# cpsw_port register map
Vendor: Texas Instruments
Peripheral module from a debugger description file (folder am335x).
Registers are 32-bit, read-write, no defined reset value unless marked. A register's access mark holds for its fields unless they carry their own. Offsets are as the file gives them; lines under a group give offsets from that group; [hi:lo] are bit positions; {n}, {i} and the like mark numbered series; 'fields as' and 'values as' point back to an identical list; <NAME> marks a mode.

## cpsw_port
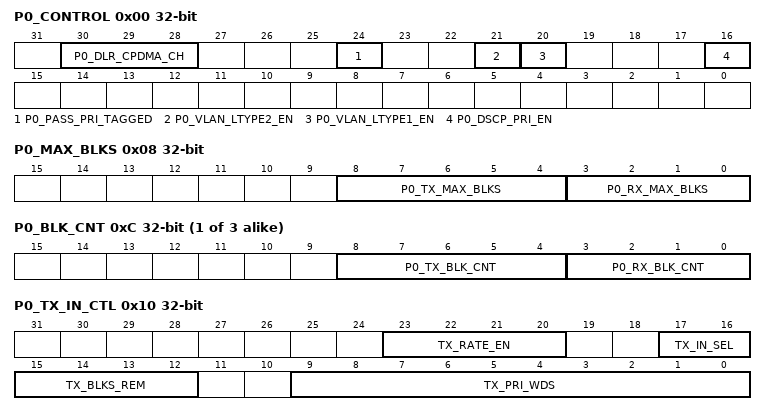
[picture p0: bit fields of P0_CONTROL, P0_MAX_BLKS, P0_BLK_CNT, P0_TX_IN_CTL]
0x00 P0_CONTROL — CPSW PORT 0 CONTROL REGISTER
  [30:28] P0_DLR_CPDMA_CH — Port 0 DLR CPDMA Channel This field indicates the CPDMA channel that DLR packets will be received on.
  [24] P0_PASS_PRI_TAGGED — Port 0 Pass Priority Tagged 0 - Priority tagged packets have the zero VID replaced with the input port P0_PORT_VLAN[11:0] 1 - Priority tagged packets are processed unchanged.
  [21] P0_VLAN_LTYPE2_EN — Port 0 VLAN LTYPE 2 enable 0 - disabled 1 - enabled
  [20] P0_VLAN_LTYPE1_EN — Port 0 VLAN LTYPE 1 enable 0 - disabled 1 - enabled
  [16] P0_DSCP_PRI_EN — Port 0 DSCP Priority Enable 0 - DSCP priority disabled 1 - DSCP priority enabled. All non-tagged IPV4 packets have their received packet priority determined by mapping the 6 TOS bits through the port DSCP priority mapping registers.
0x08 P0_MAX_BLKS — CPSW PORT 0 MAXIMUM FIFO BLOCKS REGISTER
  [8:4] P0_TX_MAX_BLKS — Transmit FIFO Maximum Blocks - This value is the maximum number of 1k memory blocks that may be allocated to the FIFO's logical transmit priority queues. 0x10 is the recommended value of p0_tx_max_blks. Port 0 should remain in flow control mode. 0xe is the minimum value tx max blks.
  [3:0] P0_RX_MAX_BLKS — Receive FIFO Maximum Blocks - This value is the maximum number of 1k memory blocks that may be allocated to the FIFO's logical receive queue. 0x4 is the recommended value. 0x3 is the minimum value rx max blks and 0x6 is the maximum value.
{0xC+0x100*i} P{i}_BLK_CNT ro (i=0..2) — CPSW PORT {i} FIFO BLOCK USAGE COUNT (READ ONLY)
  [8:4] P{i}_TX_BLK_CNT — Port {i} Transmit Block Count Usage - This value is the number of blocks allocated to the FIFO logical transmit queues.
  [3:0] P{i}_RX_BLK_CNT — Port {i} Receive Block Count Usage - This value is the number of blocks allocated to the FIFO logical receive queues.
0x10 P0_TX_IN_CTL — CPSW PORT 0 TRANSMIT FIFO CONTROL
  [23:20] TX_RATE_EN — Transmit FIFO Input Rate Enable
  [17:16] TX_IN_SEL — Transmit FIFO Input Queue Type Select 00 - Normal priority mode 01 - Dual MAC mode 10 - Rate Limit mode 11 - reserved Note that Dual MAC mode is not compatible with escalation or shaping because dual mac mode forces round robin priority on FIFO egress.
  [15:12] TX_BLKS_REM — Transmit FIFO Input Blocks to subtract in dual mac mode
  [9:0] TX_PRI_WDS — Transmit FIFO Words in queue
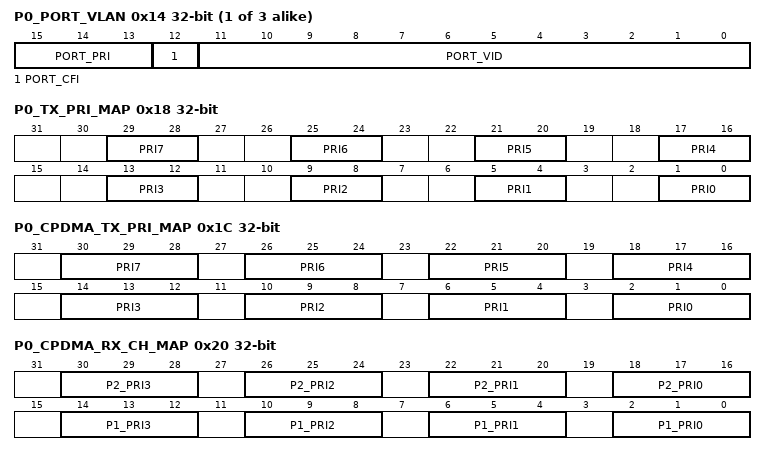
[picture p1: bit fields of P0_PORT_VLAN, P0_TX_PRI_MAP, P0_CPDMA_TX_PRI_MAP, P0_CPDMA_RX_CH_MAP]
{0x14+0x100*i} P{i}_PORT_VLAN (i=0..2) — CPSW PORT {i} VLAN REGISTER
  [15:13] PORT_PRI — Port VLAN Priority (7 is highest priority)
  [12] PORT_CFI — Port CFI bit
  [11:0] PORT_VID — Port VLAN ID
0x18 P0_TX_PRI_MAP — CPSW PORT 0 TX HEADER PRI TO SWITCH PRI MAPPING REGISTER
  [4n+1:4n] PRI{n} (n=0..7) — Priority {n} - A packet header priority of {0x0+n} is given this switch queue pri.
0x1C P0_CPDMA_TX_PRI_MAP — CPSW CPDMA TX (PORT 0 RX) PKT PRIORITY TO HEADER PRIORITY
  [4n+2:4n] PRI{n} (n=0..7) — Priority {n} - A packet pri of {0x0+n} is mapped (changed) to this header packet pri.
0x20 P0_CPDMA_RX_CH_MAP — CPSW CPDMA RX (PORT 0 TX) SWITCH PRIORITY TO DMA CHANNEL
  [4n+18:4n+16] P2_PRI{n} (n=0..3) — Port 2 Priority {n} packets go to this CPDMA Rx Channel
  [4n+2:4n] P1_PRI{n} (n=0..3) — Port 1 Priority {n} packets go to this CPDMA Rx Channel
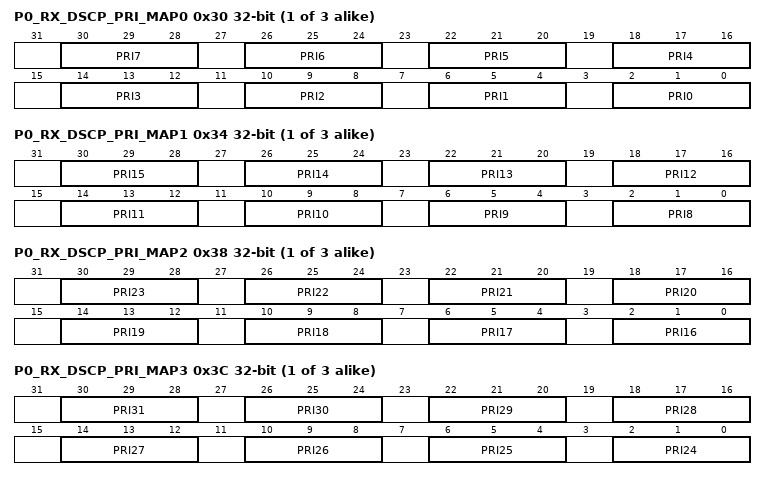
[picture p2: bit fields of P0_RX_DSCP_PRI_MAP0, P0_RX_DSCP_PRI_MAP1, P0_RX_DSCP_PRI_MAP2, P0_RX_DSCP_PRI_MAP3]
{0x30+0x100*i} P{i}_RX_DSCP_PRI_MAP0 (i=0..2) — CPSW PORT {i} RX DSCP PRIORITY TO RX PACKET MAPPING REG 0
  [4n+2:4n] PRI{n} (n=0..7) — Priority {n} - A packet TOS of 0d{n} is mapped to this received packet priority.
{0x34+0x100*i} P{i}_RX_DSCP_PRI_MAP1 (i=0..2) — CPSW PORT {i} RX DSCP PRIORITY TO RX PACKET MAPPING REG 1
  [4n-30:4n-32] PRI{n} (n=8..15) — Priority {n} - A packet TOS of 0d{n} is mapped to this received packet priority.
{0x38+0x100*i} P{i}_RX_DSCP_PRI_MAP2 (i=0..2) — CPSW PORT {i} RX DSCP PRIORITY TO RX PACKET MAPPING REG 2
  [4n-62:4n-64] PRI{n} (n=16..23) — Priority {n} - A packet TOS of 0d{n} is mapped to this received packet priority.
{0x3C+0x100*i} P{i}_RX_DSCP_PRI_MAP3 (i=0..2) — CPSW PORT {i} RX DSCP PRIORITY TO RX PACKET MAPPING REG 3
  [30:28] PRI31 — Priority 31 - A packet TOS of 0d31 is mapped to this received packet priority.
  [26:24] PRI30 — Priority 30 - A packet TOS of 0d30 is mapped to this received packet priority.
  [22:20] PRI29 — Priority 29 - A packet TOS of 0d39 is mapped to this received packet priority.
  [4n-94:4n-96] PRI{n} (n=24..28) — Priority {n} - A packet TOS of 0d{n} is mapped to this received packet priority.
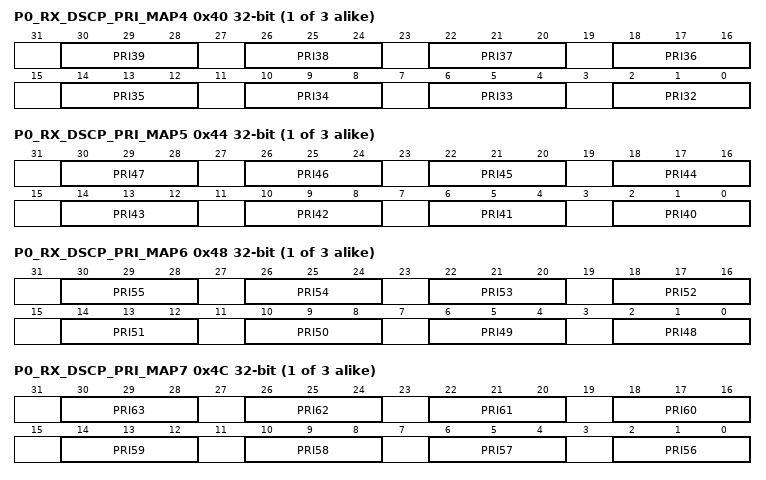
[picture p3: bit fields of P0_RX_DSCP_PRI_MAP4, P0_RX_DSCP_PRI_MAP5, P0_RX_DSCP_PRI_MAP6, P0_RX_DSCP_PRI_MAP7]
{0x40+0x100*i} P{i}_RX_DSCP_PRI_MAP4 (i=0..2) — CPSW PORT {i} RX DSCP PRIORITY TO RX PACKET MAPPING REG 4
  [4n-126:4n-128] PRI{n} (n=32..39) — Priority {n} - A packet TOS of 0d{n} is mapped to this received packet priority.
{0x44+0x100*i} P{i}_RX_DSCP_PRI_MAP5 (i=0..2) — CPSW PORT {i} RX DSCP PRIORITY TO RX PACKET MAPPING REG 5
  [4n-158:4n-160] PRI{n} (n=40..47) — Priority {n} - A packet TOS of 0d{n} is mapped to this received packet priority.
{0x48+0x100*i} P{i}_RX_DSCP_PRI_MAP6 (i=0..2) — CPSW PORT {i} RX DSCP PRIORITY TO RX PACKET MAPPING REG 6
  [4n-190:4n-192] PRI{n} (n=48..55) — Priority {n} - A packet TOS of 0d{n} is mapped to this received packet priority.
{0x4C+0x100*i} P{i}_RX_DSCP_PRI_MAP7 (i=0..2) — CPSW PORT {i} RX DSCP PRIORITY TO RX PACKET MAPPING REG 7
  [4n-222:4n-224] PRI{n} (n=56..63) — Priority {n} - A packet TOS of 0d{n} is mapped to this received packet priority.
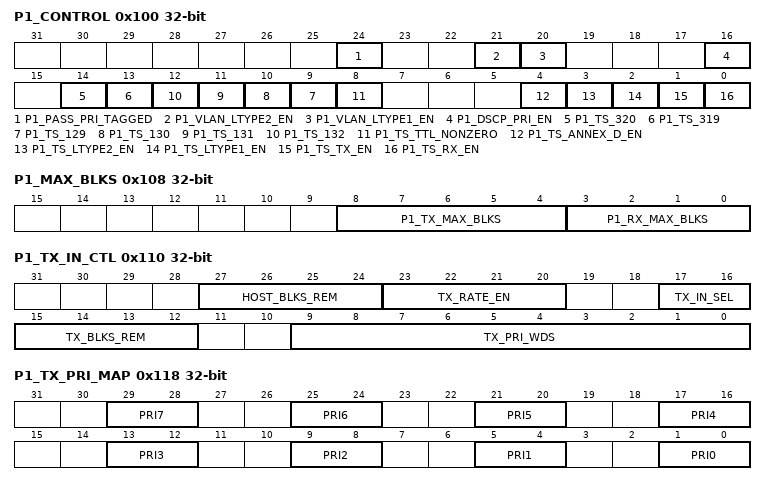
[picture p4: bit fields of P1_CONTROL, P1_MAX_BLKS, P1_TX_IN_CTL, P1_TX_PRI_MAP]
0x100 P1_CONTROL access per field — CPSW PORT 1 CONTROL REGISTER
  [24] P1_PASS_PRI_TAGGED rw — Port 1 Pass Priority Tagged 0 - Priority tagged packets have the zero VID replaced with the input port P1_PORT_VLAN[11:0] 1 - Priority tagged packets are processed unchanged.
  [21] P1_VLAN_LTYPE2_EN rw — Port 1 VLAN LTYPE 2 enable 0 - disabled 1 - VLAN LTYPE2 enabled on transmit and receive
  [20] P1_VLAN_LTYPE1_EN rw — Port 1 VLAN LTYPE 1 enable 0 - disabled 1 - VLAN LTYPE1 enabled on transmit and receive
  [16] P1_DSCP_PRI_EN rw — Port 1 DSCP Priority Enable 0 - DSCP priority disabled 1 - DSCP priority enabled. All non-tagged IPV4 packets have their received packet priority determined by mapping the 6 TOS bits through the port DSCP priority mapping registers.
  [14] P1_TS_320 rw — Port 1 Time Sync Destination Port Number 320 enable 0 - disabled 1 - Annex D (UDP/IPv4) time sync packet destination port number 320 (decimal) is enabled.
  [13] P1_TS_319 rw — Port 1 Time Sync Destination Port Number 319 enable 0 - disabled 1 - Annex D (UDP/IPv4) time sync packet destination port number 319 (decimal) is enabled.
  [n-120] P1_TS_{n} rw (n=129..132) — Port 1 Time Sync Destination IP Address {n} enable 0 - disabled 1 - Annex D (UDP/IPv4) time sync packet destination IP address number {n} (decimal) is enabled.
  [8] P1_TS_TTL_NONZERO rw — Port 1 Time Sync Time To Live Non-zero enable. 0 = TTL must be zero. 1 = TTL may be any value.
  [4] P1_TS_ANNEX_D_EN rw — Port 1 Time Sync Annex D enable 0 - Annex D disabled 1 - Annex D enabled
  [3] P1_TS_LTYPE2_EN ro — Port 1 Time Sync LTYPE 2 enable 0 - disabled 1 - enabled
  [2] P1_TS_LTYPE1_EN rw — Port 1 Time Sync LTYPE 1 enable 0 - disabled 1 - enabled
  [1] P1_TS_TX_EN rw — Port 1 Time Sync Transmit Enable 0 - disabled 1 - enabled
  [0] P1_TS_RX_EN rw — Port 1 Time Sync Receive Enable 0 - Port 1 Receive Time Sync disabled 1 - Port 1 Receive Time Sync enabled
0x108 P1_MAX_BLKS — CPSW PORT 1 MAXIMUM FIFO BLOCKS REGISTER
  [8:4] P1_TX_MAX_BLKS — Transmit FIFO Maximum Blocks - This value is the maximum number of 1k memory blocks that may be allocated to the FIFO's logical transmit priority queues. 0x11 is the recommended value of p1_tx_max_blks unless the port is in fullduplex flow control mode. In flow control mode, the p1_rx_max_blks will need to increase in order to accept the required run out in fullduplex mode. This value will need to decrease by the amount of increase in p1_rx_max_blks. 0xe is the minimum value tx max blks.
  [3:0] P1_RX_MAX_BLKS — Receive FIFO Maximum Blocks - This value is the maximum number of 1k memory blocks that may be allocated to the FIFO's logical receive queue. This value must be greater than or equal to 0x3. It should be increased In fullduplex flow control mode to 0x5 or 0x6 depending on the required runout space. The p1_tx_max_blks value must be decreased by the amount of increase in p1_rx_max_blks. 0x3 is the minimum value rx max blks and 0x6 is the maximum value.
0x110 P1_TX_IN_CTL — CPSW PORT 1 TRANSMIT FIFO CONTROL
  [27:24] HOST_BLKS_REM — Transmit FIFO Blocks that must be free before a non rate-limited CPDMA channel can begin sending a packet to the FIFO.
  [23:20] TX_RATE_EN — Transmit FIFO Input Rate Enable
  [17:16] TX_IN_SEL — Transmit FIFO Input Queue Type Select 00 - Normal priority mode 01 - reserved 10 - Rate Limit mode 11 - reserved
  [15:12] TX_BLKS_REM — Transmit FIFO Input Blocks to subtract in dual mac mode and blocks to subtract on non rate-limited traffic in rate-limit mode.
  [9:0] TX_PRI_WDS — Transmit FIFO Words in queue
0x118 P1_TX_PRI_MAP — CPSW PORT 1 TX HEADER PRIORITY TO SWITCH PRI MAPPING REGISTER
  fields as P0_TX_PRI_MAP
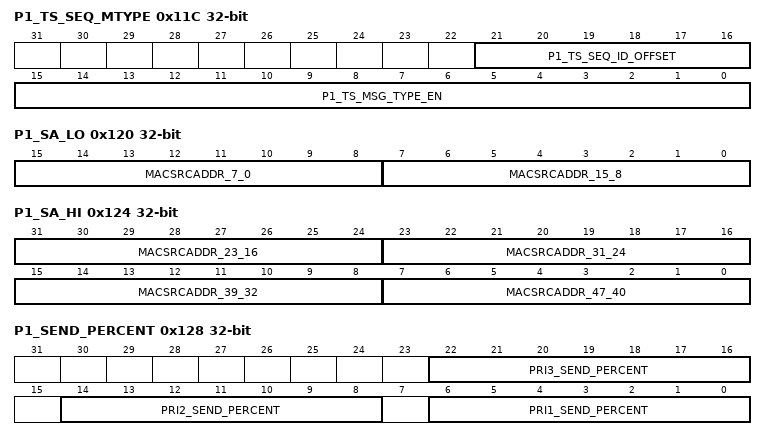
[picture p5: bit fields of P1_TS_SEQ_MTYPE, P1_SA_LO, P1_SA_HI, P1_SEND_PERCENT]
0x11C P1_TS_SEQ_MTYPE — CPSW PORT 1 TIME SYNC SEQUENCE ID OFFSET AND MSG TYPE.
  [21:16] P1_TS_SEQ_ID_OFFSET — Port 1 Time Sync Sequence ID Offset This is the number of octets that the sequence ID is offset in the tx and rx time sync message header. The minimum value is 6.
  [15:0] P1_TS_MSG_TYPE_EN — Port 1 Time Sync Message Type Enable - Each bit in this field enables the corresponding message type in receive and transmit time sync messages (Bit 0 enables message type 0 etc.).
0x120 P1_SA_LO — CPSW CPGMAC_SL1 SOURCE ADDRESS LOW REGISTER
  [15:8] MACSRCADDR_7_0 — Source Address Lower 8 bits (byte 0)
  [7:0] MACSRCADDR_15_8 — Source Address bits 15:8 (byte 1)
0x124 P1_SA_HI — CPSW CPGMAC_SL1 SOURCE ADDRESS HIGH REGISTER
  [31:24] MACSRCADDR_23_16 — Source Address bits 23:16 (byte 2)
  [23:16] MACSRCADDR_31_24 — Source Address bits 31:24 (byte 3)
  [15:8] MACSRCADDR_39_32 — Source Address bits 39:32 (byte 4)
  [7:0] MACSRCADDR_47_40 — Source Address bits 47:40 (byte 5)
0x128 P1_SEND_PERCENT — CPSW PORT 1 TRANSMIT QUEUE SEND PERCENTAGES
  [22:16] PRI3_SEND_PERCENT — Priority 3 Transmit Percentage - This percentage value is sent from FIFO priority 3 (maximum) when the p1_pri3_shape_en is set (queue shaping enabled). This is the percentage of the wire that packets from priority 3 receive (which includes interpacket gap and preamble bytes). If shaping is enabled on this queue then this value must be between zero and 0d100 (not inclusive).
  [14:8] PRI2_SEND_PERCENT — Priority 2 Transmit Percentage - This percentage value is sent from FIFO priority 2 (maximum) when the p1_pri2_shape_en is set (queue shaping enabled). This is the percentage of the wire that packets from priority 2 receive (which includes interpacket gap and preamble bytes). If shaping is enabled on this queue then this value must be between zero and 0d100 (not inclusive).
  [6:0] PRI1_SEND_PERCENT — Priority 1 Transmit Percentage - This percentage value is sent from FIFO priority 1 (maximum) when the p1_pri1_shape_en is set (queue shaping enabled). This is the percentage of the wire that packets from priority 1 receive (which includes interpacket gap and preamble bytes). If shaping is enabled on this queue then this value must be between zero and 0d100 (not inclusive).
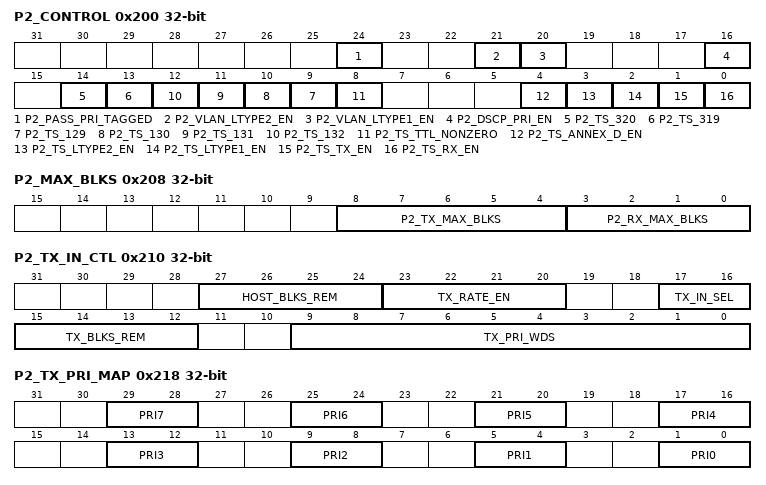
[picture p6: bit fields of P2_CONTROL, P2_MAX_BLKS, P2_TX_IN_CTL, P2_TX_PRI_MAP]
0x200 P2_CONTROL access per field — CPSW_3GF PORT 2 CONTROL REGISTER
  [24] P2_PASS_PRI_TAGGED rw — Port 2 Pass Priority Tagged 0 - Priority tagged packets have the zero VID replaced with the input port P2_PORT_VLAN[11:0] 1 - Priority tagged packets are processed unchanged.
  [21] P2_VLAN_LTYPE2_EN rw — Port 2 VLAN LTYPE 2 enable 0 - disabled 1 - VLAN LTYPE2 enabled on transmit and receive
  [20] P2_VLAN_LTYPE1_EN rw — Port 2 VLAN LTYPE 1 enable 0 - disabled 1 - VLAN LTYPE1 enabled on transmit and receive
  [16] P2_DSCP_PRI_EN rw — Port 0 DSCP Priority Enable 0 - DSCP priority disabled 1 - DSCP priority enabled. All non-tagged IPV4 packets have their received packet priority determined by mapping the 6 TOS bits through the port DSCP priority mapping registers.
  [14] P2_TS_320 rw — Port 2 Time Sync Destination Port Number 320 enable 0 - disabled 1 - Annex D (UDP/IPv4) time sync packet destination port number 320 (decimal) is enabled.
  [13] P2_TS_319 rw — Port 2 Time Sync Destination Port Number 319 enable 0 - disabled 1 - Annex D (UDP/IPv4) time sync packet destination port number 319 (decimal) is enabled.
  [n-120] P2_TS_{n} rw (n=129..132) — Port 2 Time Sync Destination IP Address {n} enable 0 - disabled 1 - Annex D (UDP/IPv4) time sync packet destination IP address number {n} (decimal) is enabled.
  [8] P2_TS_TTL_NONZERO rw — Port 2 Time Sync Time To Live Non-zero enable. 0 = TTL must be zero. 1 = TTL may be any value.
  [4] P2_TS_ANNEX_D_EN rw — Port 2 Time Sync Annex D enable 0 - Annex D disabled 1 - Annex D enabled
  [3] P2_TS_LTYPE2_EN ro — Port 2 Time Sync LTYPE 2 enable 0 - disabled 1 - enabled
  [2] P2_TS_LTYPE1_EN rw — Port 2 Time Sync LTYPE 1 enable 0 - disabled 1 - enabled
  [1] P2_TS_TX_EN rw — Port 2 Time Sync Transmit Enable 0 - disabled 1 - enabled
  [0] P2_TS_RX_EN rw — Port 2 Time Sync Receive Enable 0 - Port 1 Receive Time Sync disabled 1 - Port 1 Receive Time Sync enabled
0x208 P2_MAX_BLKS — CPSW PORT 2 MAXIMUM FIFO BLOCKS REGISTER
  [8:4] P2_TX_MAX_BLKS — Transmit FIFO Maximum Blocks - This value is the maximum number of 1k memory blocks that may be allocated to the FIFO's logical transmit priority queues. 0x11 is the recommended value of p2_tx_max_blks unless the port is in fullduplex flow control mode. In flow control mode, the p2_rx_max_blks will need to increase in order to accept the required run out in fullduplex mode. This value will need to decrease by the amount of increase in p2_rx_max_blks. 0xe is the minimum value tx max blks.
  [3:0] P2_RX_MAX_BLKS — Receive FIFO Maximum Blocks - This value is the maximum number of 1k memory blocks that may be allocated to the FIFO's logical receive queue. This value must be greater than or equal to 0x3. It should be increased In fullduplex flow control mode to 0x5 or 0x6 depending on the required runout space. The p2_tx_max_blks value must be decreased by the amount of increase in p2_rx_max_blks. 0x3 is the minimum value rx max blks and 0x6 is the maximum value.
0x210 P2_TX_IN_CTL — CPSW PORT 2 TRANSMIT FIFO CONTROL
  fields as P1_TX_IN_CTL
0x218 P2_TX_PRI_MAP — CPSW PORT 2 TX HEADER PRIORITY TO SWITCH PRI MAPPING REGISTER
  fields as P0_TX_PRI_MAP
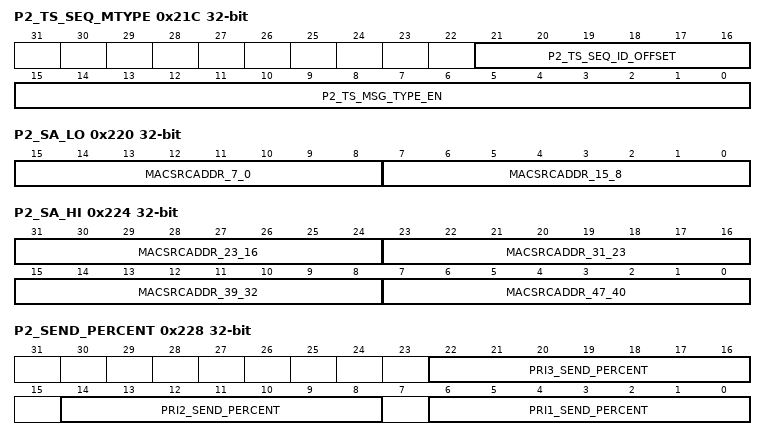
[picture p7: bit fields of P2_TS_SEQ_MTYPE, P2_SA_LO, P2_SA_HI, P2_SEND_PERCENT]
0x21C P2_TS_SEQ_MTYPE — CPSW_3GF PORT 2 TIME SYNC SEQUENCE ID OFFSET AND MSG TYPE.
  [21:16] P2_TS_SEQ_ID_OFFSET — Port 2 Time Sync Sequence ID Offset This is the number of octets that the sequence ID is offset in the tx and rx time sync message header. The minimum value is 6.
  [15:0] P2_TS_MSG_TYPE_EN — Port 2 Time Sync Message Type Enable - Each bit in this field enables the corresponding message type in receive and transmit time sync messages (Bit 0 enables message type 0 etc.).
0x220 P2_SA_LO — CPSW CPGMAC_SL2 SOURCE ADDRESS LOW REGISTER
  fields as P1_SA_LO
0x224 P2_SA_HI — CPSW CPGMAC_SL2 SOURCE ADDRESS HIGH REGISTER
  [31:24] MACSRCADDR_23_16 — Source Address bits 23:16 (byte 2)
  [23:16] MACSRCADDR_31_23 — Source Address bits 31:23 (byte 3)
  [15:8] MACSRCADDR_39_32 — Source Address bits 39:32 (byte 4)
  [7:0] MACSRCADDR_47_40 — Source Address bits 47:40 (byte 5)
0x228 P2_SEND_PERCENT — CPSW PORT 2 TRANSMIT QUEUE SEND PERCENTAGES
  fields as P1_SEND_PERCENT
